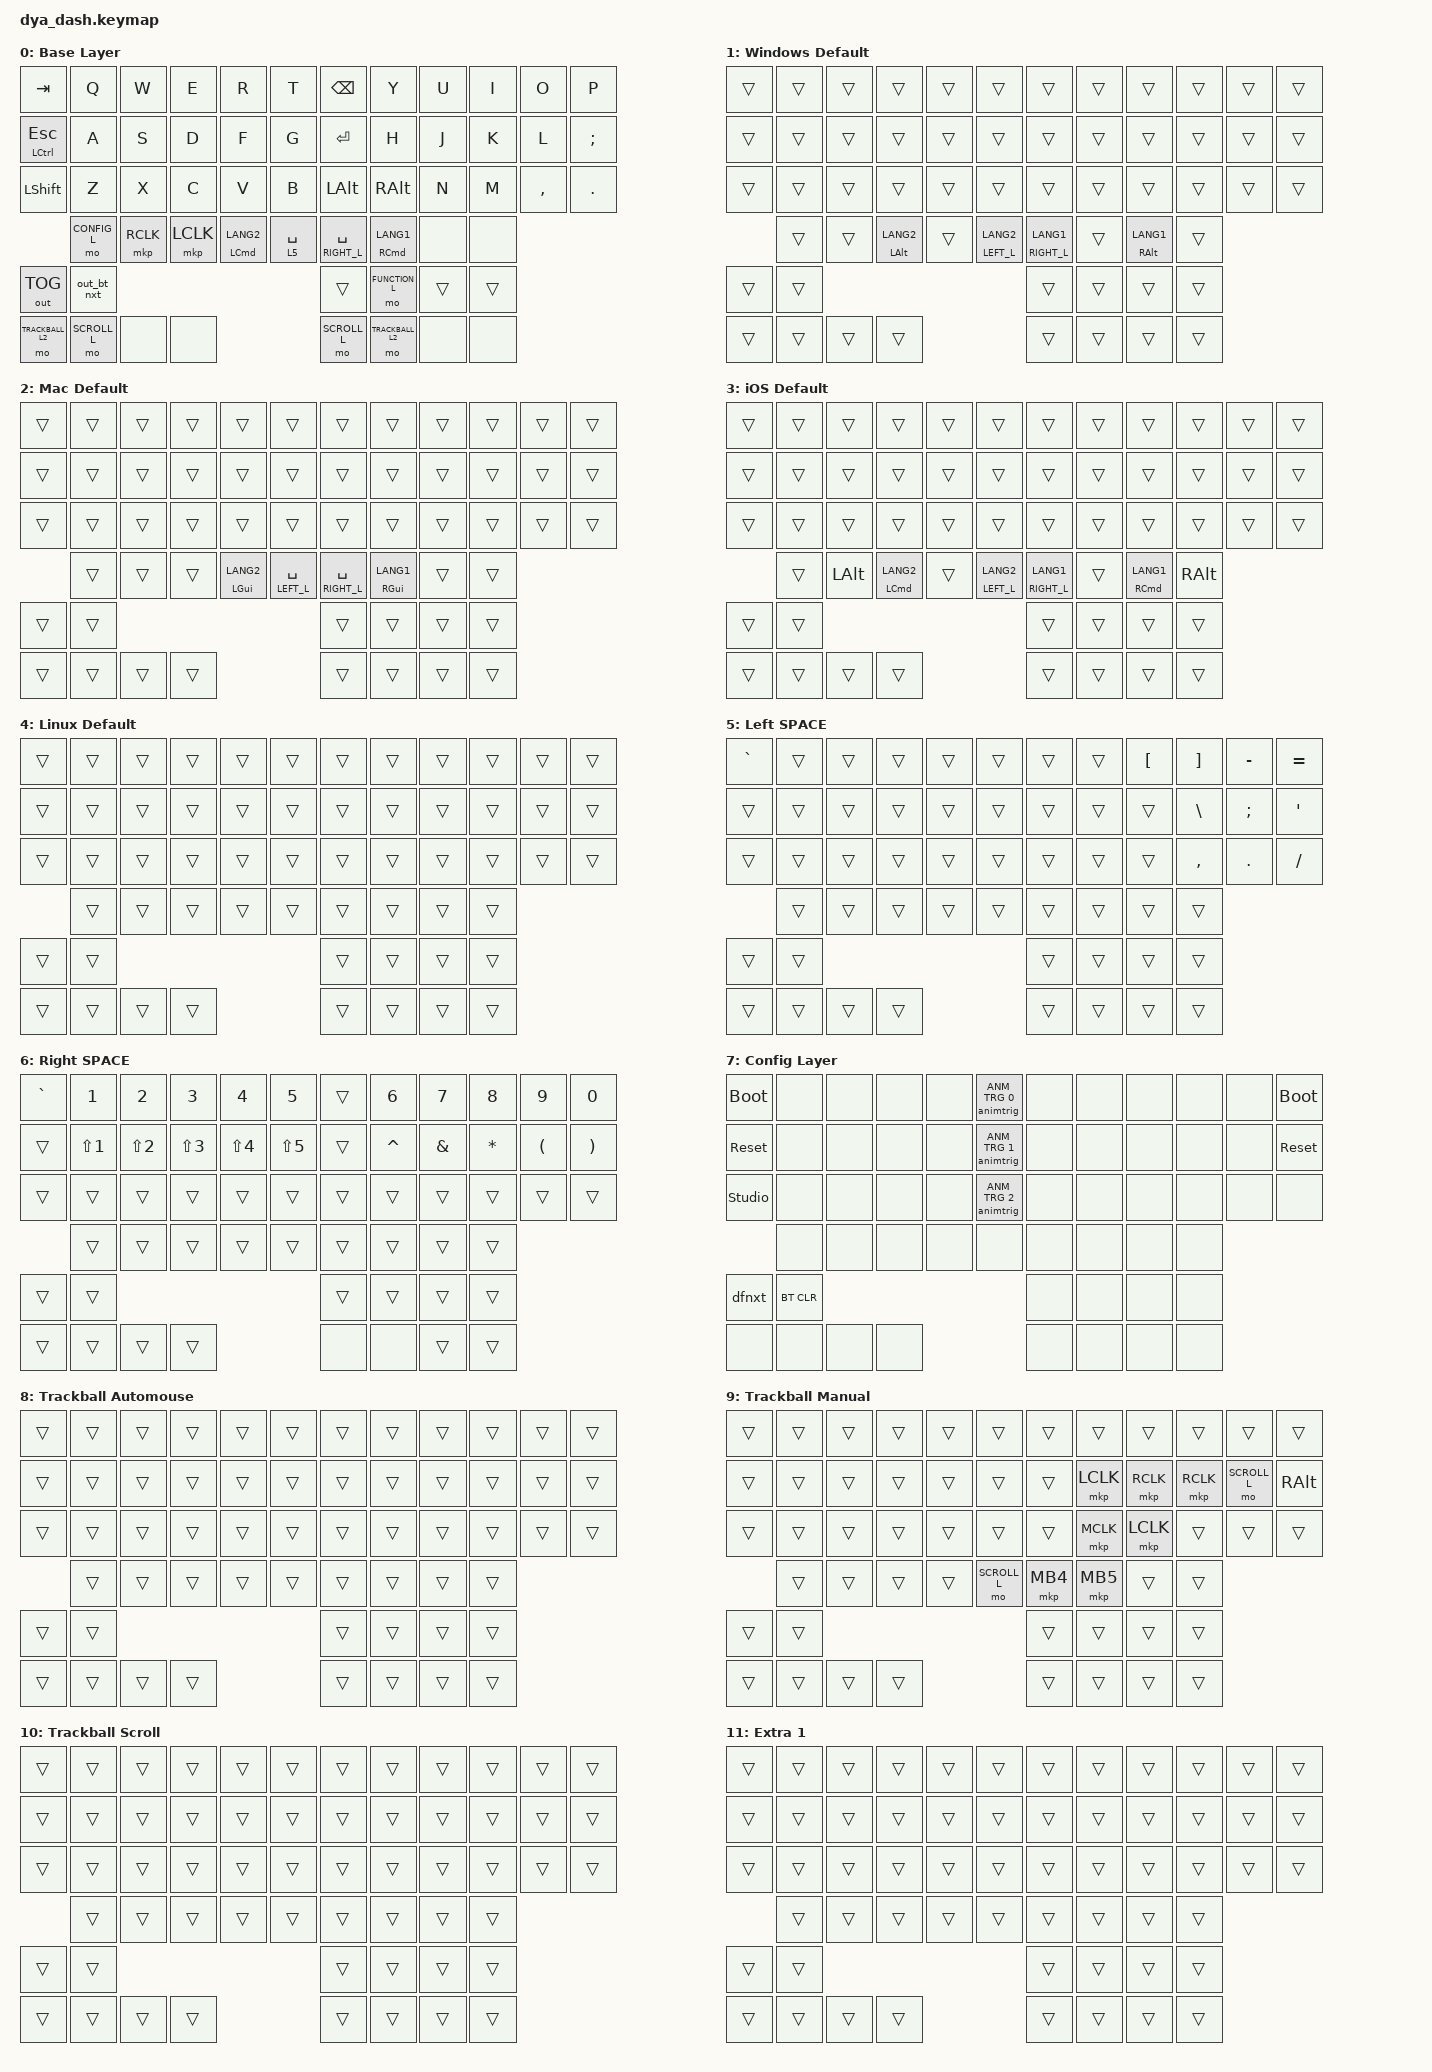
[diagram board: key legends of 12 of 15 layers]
#include <behaviors/mouse_move.dtsi>
#include <behaviors/animation_control.dtsi>
#include <behaviors/animation_trigger.dtsi>
#include <dt-bindings/zmk/mouse.h>
#include <dt-bindings/zmk_driver_animation/animation_control.h>
#include <dt-bindings/zmk_driver_animation/animation_trigger.h>
#include <dt-bindings/zmk_behavior_default_layer/default_layer.h>
#include <behaviors.dtsi>
#include <dt-bindings/zmk/bt.h>
#include <dt-bindings/zmk/keys.h>
#include <dt-bindings/zmk/outputs.h>
#include <dt-bindings/zmk/pointing.h>

// Layer definitions

#define DEFAULT_L 0
#define WINDOWS_L 1
#define MAC_L 2
#define IOS_L 3
#define LINUX_L 4
#define LEFT_L 5
#define RIGHT_L 6
#define CONFIG_L 7
#define TRACKBALL_L 8
#define TRACKBALL_L2 9
#define SCROLL_L 10
#define EXT1_L 11
#define EXT2_L 12
#define EXT3_L 13
#define FUNCTION_L 14

&trackball_listener {
    input-processors = <
    // TRACKBALL_L layer is activated when trackball is used.
    // After 500ms of trackball inactivity, the layer is deactivated.
    &zip_temp_layer TRACKBALL_L 500
    // Example: Adjust sensitivity of trackball multiply by 1 and divide by 60.
    // &zip_xy_scaler 1 60
    >;
};

&trackball_scroller {
    layers = <SCROLL_L>;

    // Example: adjust sensitivity of scroll multiply by 1 and divide by 60.
    // input-processors = <&zip_xy_scaler 1 60 &zip_xy_to_scroll_mapper>;
};

&trackball_listener_l { input-processors = <&zip_temp_layer TRACKBALL_L 500>; };

&trackball_scroller_l { layers = <SCROLL_L>; };

&zip_temp_layer { excluded-positions = <19 20 21 22 32 33 41 52 53 54 55 56 57 58 59>; };

&trackball_r { cpi = <600>; };

&trackball_l { cpi = <600>; };

/ {
    behaviors {
        // ctrl+h as backspace

        hbackspace: h_or_ctrl_backspace {
            compatible = "zmk,behavior-mod-morph";
            #binding-cells = <0>;
            bindings = <&kp H>, <&kp BACKSPACE>;

            mods = <(MOD_LCTL)>;
        };

        // ctrl+j as enter

        jenter: j_or_ctrl_enter {
            compatible = "zmk,behavior-mod-morph";
            #binding-cells = <0>;
            bindings = <&kp J>, <&kp ENTER>;

            mods = <(MOD_LCTL)>;
        };
    };

    macros {
        // Disconnect from all once for reliable connection to selected profile.
        // ZMK automatically reconnects to current profile right after disconnection.

        out_bt_nxt: out_bt_nxt {
            compatible = "zmk,behavior-macro";
            #binding-cells = <0>;
            wait-ms = <50>;
            bindings = <&out OUT_BLE &bt BT_NXT &bt BT_DISC 0 &bt BT_DISC 1 &bt BT_DISC 2 &bt BT_DISC 3 &bt BT_DISC 4>;
        };

        // Change default layer for current profile to next layer

        dfnxt: dfnxt {
            compatible = "zmk,behavior-macro";
            #binding-cells = <0>;
            bindings = <&df DF_INC &animtrig ANM_TRG 2>;
        };
    };

    combos {
        compatible = "zmk,combos";

        // Right side's setting button shares input pin with arrow keys.
        // It works as a combo of two arrow keys.

        setting_r1 {
            timeout-ms = <10>;
            key-positions = <47 50>;
            bindings = <&kp C_VOL_DN>;
        };

        setting_r2 {
            timeout-ms = <10>;
            key-positions = <47 49>;
            bindings = <&kp C_VOL_UP>;
        };

        left_bracket {
            bindings = <&kp LEFT_BRACKET>;
            key-positions = <10 9>;
            layers = <0>;
        };

        right_bracket {
            bindings = <&kp RIGHT_BRACKET>;
            key-positions = <10 11>;
            layers = <0>;
        };

        right_click {
            bindings = <&mkp RCLK>;
            key-positions = <30 18>;
        };

        equal {
            bindings = <&kp EQUAL>;
            key-positions = <10 11>;
            layers = <6>;
        };
    };

    keymap {
        compatible = "zmk,keymap";

        // template {
        //     bindings = <
        //         &trans      &trans      &trans      &trans      &trans      &trans      /**/ &trans      &trans      &trans      &trans      &trans      &trans
        //         &trans      &trans      &trans      &trans      &trans      &trans      /**/ &trans      &trans      &trans      &trans      &trans      &trans
        //         &trans      &trans      &trans      &trans      &trans      &trans      /**/ &trans      &trans      &trans      &trans      &trans      &trans
        //                     &trans      &trans      &trans      &trans      &trans      /**/ &trans      &trans      &trans      &trans
        //
        //         &trans      &trans                                                      /**/ &trans      &trans      &trans      &trans
        //         &trans      &trans      &trans      &trans                              /**/ &trans      &trans      &trans      &trans
        //     >;
        // };

        default_layer {
            display-name = "Base Layer";

            // --------------------------------------------------------------------------------------------------------------------------------------------------
            // |   TAB   |    Q    |    W    |    E    |    R    |    T       |            |    Y        |    U    |    I     |    O    |    P    |    [    |
            // |   CTRL  |    A    |    S    |    D    |    F    |    G       |            |    H        |    J    |    K     |    L    |    ;    |    '    |
            // |  SHIFT  |    Z    |    X    |    C    |    V    |    B       |            |    B        |    N    |    M     |    ,    |    .    |    /    |
            //           |  CONFIG |   WIN   |   ALT   |  SPACE  | LEFT_LAYER |            | RIGHT_LAYER |  SPACE  |   ALT    |   WIN   |
            // --------------------------------------------------------------------------------------------------------------------------------------------------
            // | BLE     |  USB    |                                                       |  left   | up      | down    | right   |
            // | touch1  | touch2  | touch3  | touch 4 |                                   | touch1  | touch2  | touch3  | touch 4 |

            bindings = <
&kp TAB           &kp Q         &kp W      &kp E      &kp R                   &kp T        &kp BSPC           &kp Y                    &kp U   &kp I   &kp O      &kp P
&mt LCTRL ESCAPE  &kp A         &kp S      &kp D      &kp F                   &kp G        &kp ENTER          &kp H                    &kp J   &kp K   &kp L      &kp SEMI
&kp LSHIFT        &kp Z         &kp X      &kp C      &kp V                   &kp B        &kp LALT           &kp RIGHT_ALT            &kp N   &kp M   &kp COMMA  &kp DOT
                  &mo CONFIG_L  &mkp RCLK  &mkp LCLK  &mt LEFT_COMMAND LANG2  &lt 5 SPACE  &lt RIGHT_L SPACE  &mt RIGHT_COMMAND LANG1  &none   &none
&out OUT_TOG      &out_bt_nxt                                                              &trans             &mo FUNCTION_L           &trans  &trans
&mo TRACKBALL_L2  &mo SCROLL_L  &none      &none                                           &mo SCROLL_L       &mo TRACKBALL_L2         &none   &none
            >;
        };

        windows_default_layer {
            display-name = "Windows Default";
            bindings = <
&trans  &trans  &trans  &trans          &trans  &trans            &trans             &trans  &trans          &trans  &trans  &trans
&trans  &trans  &trans  &trans          &trans  &trans            &trans             &trans  &trans          &trans  &trans  &trans
&trans  &trans  &trans  &trans          &trans  &trans            &trans             &trans  &trans          &trans  &trans  &trans
        &trans  &trans  &mt LALT LANG2  &trans  &lt LEFT_L LANG2  &lt RIGHT_L LANG1  &trans  &mt RALT LANG1  &trans
&trans  &trans                                                    &trans             &trans  &trans          &trans
&trans  &trans  &trans  &trans                                    &trans             &trans  &trans          &trans
            >;
        };

        mac_default_layer {
            display-name = "Mac Default";
            bindings = <
&trans  &trans  &trans  &trans  &trans              &trans            &trans             &trans               &trans  &trans  &trans  &trans
&trans  &trans  &trans  &trans  &trans              &trans            &trans             &trans               &trans  &trans  &trans  &trans
&trans  &trans  &trans  &trans  &trans              &trans            &trans             &trans               &trans  &trans  &trans  &trans
        &trans  &trans  &trans  &mt LEFT_GUI LANG2  &lt LEFT_L SPACE  &lt RIGHT_L SPACE  &mt RIGHT_GUI LANG1  &trans  &trans
&trans  &trans                                                        &trans             &trans               &trans  &trans
&trans  &trans  &trans  &trans                                        &trans             &trans               &trans  &trans
            >;
        };

        ios_default_layer {
            display-name = "iOS Default";
            bindings = <
&trans  &trans  &trans    &trans          &trans  &trans            &trans             &trans  &trans          &trans    &trans  &trans
&trans  &trans  &trans    &trans          &trans  &trans            &trans             &trans  &trans          &trans    &trans  &trans
&trans  &trans  &trans    &trans          &trans  &trans            &trans             &trans  &trans          &trans    &trans  &trans
        &trans  &kp LALT  &mt LCMD LANG2  &trans  &lt LEFT_L LANG2  &lt RIGHT_L LANG1  &trans  &mt RCMD LANG1  &kp RALT
&trans  &trans                                                      &trans             &trans  &trans          &trans
&trans  &trans  &trans    &trans                                    &trans             &trans  &trans          &trans
            >;
        };

        linux_default_layer {
            display-name = "Linux Default";
            bindings = <
&trans  &trans  &trans  &trans  &trans  &trans  &trans  &trans  &trans  &trans  &trans  &trans
&trans  &trans  &trans  &trans  &trans  &trans  &trans  &trans  &trans  &trans  &trans  &trans
&trans  &trans  &trans  &trans  &trans  &trans  &trans  &trans  &trans  &trans  &trans  &trans
        &trans  &trans  &trans  &trans  &trans  &trans  &trans  &trans  &trans
&trans  &trans                                  &trans  &trans  &trans  &trans
&trans  &trans  &trans  &trans                  &trans  &trans  &trans  &trans
            >;
        };

        left_layer {
            display-name = "Left SPACE";

            // --------------------------------------------------------------------------------------------------------------------------------------------------------------------
            // |  ESC    |  !  |  @  |  #       |  $  |  %       |                           |  ^  |  &      |  *      |  (  |  )  |  ]  |
            // |         |  1  |  2  |  3       |  4  |  5       |                           |  6  |  7      |  8      |  9  |  0  |  \  |
            // |         |     |     |          |     |          |                           |  `  |  -      |  =      |  [  |  ]  |SHIFT|
            //           |     |     |          |     |          |                           |     |         |         |     |

            bindings = <
&kp GRAVE  &trans  &trans  &trans  &trans  &trans  &trans  &trans  &kp LBKT  &kp RBKT   &kp MINUS  &kp EQUAL
&trans     &trans  &trans  &trans  &trans  &trans  &trans  &trans  &trans    &kp BSLH   &kp SEMI   &kp APOS
&trans     &trans  &trans  &trans  &trans  &trans  &trans  &trans  &trans    &kp COMMA  &kp DOT    &kp FSLH
           &trans  &trans  &trans  &trans  &trans  &trans  &trans  &trans    &trans
&trans     &trans                                  &trans  &trans  &trans    &trans
&trans     &trans  &trans  &trans                  &trans  &trans  &trans    &trans
            >;
        };

        right_layer {
            display-name = "Right SPACE";
            bindings = <
&kp GRAVE  &kp N1      &kp N2      &kp N3      &kp N4      &kp N5      &trans  &kp N6     &kp N7         &kp N8        &kp N9                &kp N0
&trans     &kp LS(N1)  &kp LS(N2)  &kp LS(N3)  &kp LS(N4)  &kp LS(N5)  &trans  &kp CARET  &kp AMPERSAND  &kp ASTERISK  &kp LEFT_PARENTHESIS  &kp RIGHT_PARENTHESIS
&trans     &trans      &trans      &trans      &trans      &trans      &trans  &trans     &trans         &trans        &trans                &trans
           &trans      &trans      &trans      &trans      &trans      &trans  &trans     &trans         &trans
&trans     &trans                                                      &trans  &trans     &trans         &trans
&trans     &trans      &trans      &trans                              &none   &none      &trans         &trans
            >;
        };

        config_layer {
            display-name = "Config Layer";
            bindings = <
&bootloader     &none       &none  &none  &none  &animtrig ANM_TRG 0  &none  &none  &none  &none  &none  &bootloader
&sys_reset      &none       &none  &none  &none  &animtrig ANM_TRG 1  &none  &none  &none  &none  &none  &sys_reset
&studio_unlock  &none       &none  &none  &none  &animtrig ANM_TRG 2  &none  &none  &none  &none  &none  &none
                &none       &none  &none  &none  &none                &none  &none  &none  &none
&dfnxt          &bt BT_CLR                                            &none  &none  &none  &none
&none           &none       &none  &none                              &none  &none  &none  &none
            >;
        };

        trackball_layer {
            display-name = "Trackball Automouse";
            bindings = <
&trans  &trans  &trans  &trans  &trans  &trans  &trans  &trans  &trans  &trans  &trans  &trans
&trans  &trans  &trans  &trans  &trans  &trans  &trans  &trans  &trans  &trans  &trans  &trans
&trans  &trans  &trans  &trans  &trans  &trans  &trans  &trans  &trans  &trans  &trans  &trans
        &trans  &trans  &trans  &trans  &trans  &trans  &trans  &trans  &trans
&trans  &trans                                  &trans  &trans  &trans  &trans
&trans  &trans  &trans  &trans                  &trans  &trans  &trans  &trans
            >;
        };

        trackball_layer2 {
            display-name = "Trackball Manual";
            bindings = <
&trans  &trans  &trans  &trans  &trans  &trans        &trans    &trans     &trans     &trans     &trans        &trans
&trans  &trans  &trans  &trans  &trans  &trans        &trans    &mkp LCLK  &mkp RCLK  &mkp RCLK  &mo SCROLL_L  &kp RALT
&trans  &trans  &trans  &trans  &trans  &trans        &trans    &mkp MCLK  &mkp LCLK  &trans     &trans        &trans
        &trans  &trans  &trans  &trans  &mo SCROLL_L  &mkp MB4  &mkp MB5   &trans     &trans
&trans  &trans                                        &trans    &trans     &trans     &trans
&trans  &trans  &trans  &trans                        &trans    &trans     &trans     &trans
            >;
        };

        scroll_layer {
            display-name = "Trackball Scroll";
            bindings = <
&trans  &trans  &trans  &trans  &trans  &trans  &trans  &trans  &trans  &trans  &trans  &trans
&trans  &trans  &trans  &trans  &trans  &trans  &trans  &trans  &trans  &trans  &trans  &trans
&trans  &trans  &trans  &trans  &trans  &trans  &trans  &trans  &trans  &trans  &trans  &trans
        &trans  &trans  &trans  &trans  &trans  &trans  &trans  &trans  &trans
&trans  &trans                                  &trans  &trans  &trans  &trans
&trans  &trans  &trans  &trans                  &trans  &trans  &trans  &trans
            >;
        };

        extra1 {
            display-name = "Extra 1";
            bindings = <
&trans  &trans  &trans  &trans  &trans  &trans  &trans  &trans  &trans  &trans  &trans  &trans
&trans  &trans  &trans  &trans  &trans  &trans  &trans  &trans  &trans  &trans  &trans  &trans
&trans  &trans  &trans  &trans  &trans  &trans  &trans  &trans  &trans  &trans  &trans  &trans
        &trans  &trans  &trans  &trans  &trans  &trans  &trans  &trans  &trans
&trans  &trans                                  &trans  &trans  &trans  &trans
&trans  &trans  &trans  &trans                  &trans  &trans  &trans  &trans
            >;
        };

        extra2 {
            display-name = "Extra 2";
            bindings = <
&trans  &trans  &trans  &trans  &trans  &trans  &trans  &trans  &trans  &trans  &trans  &trans
&trans  &trans  &trans  &trans  &trans  &trans  &trans  &trans  &trans  &trans  &trans  &trans
&trans  &trans  &trans  &trans  &trans  &trans  &trans  &trans  &trans  &trans  &trans  &trans
        &trans  &trans  &trans  &trans  &trans  &trans  &trans  &trans  &trans
&trans  &trans                                  &trans  &trans  &trans  &trans
&trans  &trans  &trans  &trans                  &trans  &trans  &trans  &trans
            >;
        };

        extra3 {
            display-name = "Extra 3";
            bindings = <
&trans  &trans  &trans  &trans  &trans  &trans  &trans  &trans  &trans  &trans  &trans  &trans
&trans  &trans  &trans  &trans  &trans  &trans  &trans  &trans  &trans  &trans  &trans  &trans
&trans  &trans  &trans  &trans  &trans  &trans  &trans  &trans  &trans  &trans  &trans  &trans
        &trans  &trans  &trans  &trans  &trans  &trans  &trans  &trans  &trans
&trans  &trans                                  &trans  &trans  &trans  &trans
&trans  &trans  &trans  &trans                  &trans  &trans  &trans  &trans
            >;
        };

        function_layer {
            display-name = "Function";
            bindings = <
&kp N1                &kp N2                &kp N3                             &kp N4           &kp N5               &kp N6                  &kp N7      &kp N8            &kp N9      &kp N0      &kp MINUS          &kp EQUAL
&kp F1                &kp F2                &kp F3                             &kp F4           &kp F5               &kp F6                  &kp F7      &kp F8            &kp F9      &kp F10     &kp F11            &kp F12
&kp C_BRIGHTNESS_DEC  &kp C_BRIGHTNESS_INC  &kp C_AC_DESKTOP_SHOW_ALL_WINDOWS  &kp C_AC_SEARCH  &kp C_VOICE_COMMAND  &kp C_BACKLIGHT_TOGGLE  &kp C_PREV  &kp C_PLAY_PAUSE  &kp C_NEXT  &kp C_MUTE  &kp C_VOLUME_DOWN  &kp C_VOLUME_UP
                      &kp GLOBE             &trans                             &trans           &trans               &trans                  &trans      &trans            &trans      &trans
&trans                &trans                                                                                                                 &trans      &trans            &trans      &trans
&trans                &trans                &trans                             &trans                                                        &trans      &trans            &trans      &trans
            >;
        };
    };
};
